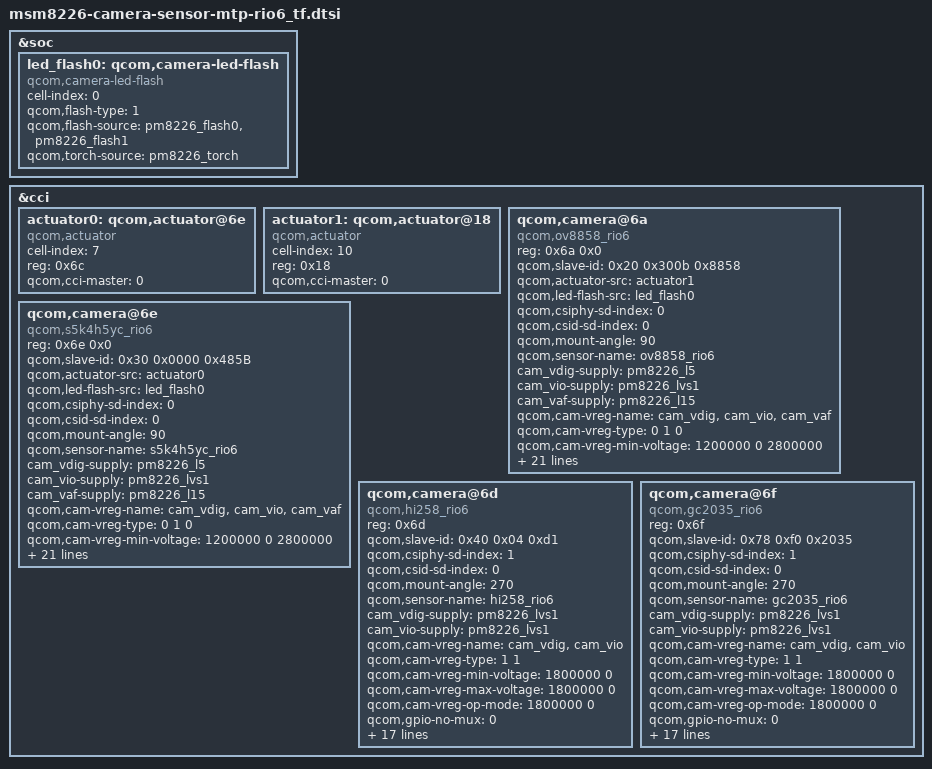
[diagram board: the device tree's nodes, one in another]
/*
 * Copyright (c) 2013, The Linux Foundation. All rights reserved.
 *
 * This program is free software; you can redistribute it and/or modify
 * it under the terms of the GNU General Public License version 2 and
 * only version 2 as published by the Free Software Foundation.
 *
 * This program is distributed in the hope that it will be useful,
 * but WITHOUT ANY WARRANTY; without even the implied warranty of
 * MERCHANTABILITY or FITNESS FOR A PARTICULAR PURPOSE.  See the
 * GNU General Public License for more details.
 *         Modify History For This Module
 * When           Who             What,Where,Why
 * --------------------------------------------------------------------------------------
 * 13/08/22      Hu Jin       Add driver for RoilTF's 1st main CAM
 * 13/12/11      Hu Jin       for i2c compatibility
 * 14/01/09      Hu Jin       Delete the old i2c
 * --------------------------------------------------------------------------------------
 */

&soc {

	led_flash0: qcom,camera-led-flash {
		cell-index = <0>;
		compatible = "qcom,camera-led-flash";
		qcom,flash-type = <1>;
		qcom,flash-source = <&pm8226_flash0 &pm8226_flash1>;
		qcom,torch-source = <&pm8226_torch>;
	};
};

&cci {

	actuator0: qcom,actuator@6e {
		cell-index = <7>;/* [PLATFORM]-Mod-BEGIN by TCTNB.HJ, 2013/11/09, 1st main CAM dev*/
		reg = <0x6c>;
		compatible = "qcom,actuator";
		qcom,cci-master = <0>;
	};
/* [PLATFORM]-Mod-BEGIN by TCTNB.HJ, 2013/12/11 */
/*
	qcom,camera@6f {
		compatible = "qcom,ov8825";
		reg = <0x6f>;
		qcom,slave-id = <0x6c 0x300a 0x8825>;
		qcom,csiphy-sd-index = <0>;
		qcom,csid-sd-index = <0>;
		qcom,actuator-src = <&actuator0>;
		qcom,led-flash-src = <&led_flash0>;
		qcom,mount-angle = <270>;
		qcom,sensor-name = "ov8825";
		cam_vdig-supply = <&pm8226_l5>;
		cam_vana-supply = <&pm8226_l19>;
		cam_vio-supply = <&pm8226_lvs1>;
		cam_vaf-supply = <&pm8226_l15>;
		qcom,cam-vreg-name = "cam_vdig", "cam_vio", "cam_vana",
							 "cam_vaf";
		qcom,cam-vreg-type = <0 1 0 0>;
		qcom,cam-vreg-min-voltage = <1200000 0 2850000 2800000>;
		qcom,cam-vreg-max-voltage = <1200000 0 2850000 2800000>;
		qcom,cam-vreg-op-mode = <200000 0 80000 100000>;
		qcom,gpio-no-mux = <0>;
		gpios = <&msmgpio 26 0>,
			<&msmgpio 37 0>,
			<&msmgpio 35 0>;
		qcom,gpio-reset = <1>;
		qcom,gpio-standby = <2>;
		qcom,gpio-req-tbl-num = <0 1 2>;
		qcom,gpio-req-tbl-flags = <1 0 0>;
		qcom,gpio-req-tbl-label = "CAMIF_MCLK",
			"CAM_RESET1",
			"CAM_STANDBY";
		qcom,csi-lane-assign = <0x4320>;
		qcom,csi-lane-mask = <0x1f>;
		qcom,sensor-position = <0>;
		qcom,sensor-mode = <1>;
		qcom,cci-master = <0>;
	};

	qcom,camera@6d {
		compatible = "qcom,ov9724";
		reg = <0x6d>;
		qcom,slave-id = <0x20 0x0 0x9724>;
		qcom,csiphy-sd-index = <1>;
		qcom,csid-sd-index = <1>;
		qcom,mount-angle = <270>;
		qcom,sensor-name = "ov9724";
		cam_vdig-supply = <&pm8226_l5>;
		cam_vana-supply = <&pm8226_l19>;
		cam_vio-supply = <&pm8226_lvs1>;
		qcom,cam-vreg-name = "cam_vdig", "cam_vio", "cam_vana";
		qcom,cam-vreg-type = <0 1 0>;
		qcom,cam-vreg-min-voltage = <1200000 0 2850000>;
		qcom,cam-vreg-max-voltage = <1200000 0 2850000>;
		qcom,cam-vreg-op-mode = <200000 0 80000>;
		qcom,gpio-no-mux = <0>;
		gpios = <&msmgpio 26 0>,
				<&msmgpio 28 0>,
				<&msmgpio 36 0>;
		qcom,gpio-reset = <1>;
		qcom,gpio-standby = <2>;
		qcom,gpio-req-tbl-num = <0 1 2>;
		qcom,gpio-req-tbl-flags = <1 0 0>;
		qcom,gpio-req-tbl-label = "CAMIF_MCLK",
				"CAM_RESET",
				"CAM_STANDBY";
		qcom,gpio-set-tbl-num = <1 1>;
		qcom,gpio-set-tbl-flags = <0 2>;
		qcom,gpio-set-tbl-delay = <1000 4000>;
		qcom,csi-lane-assign = <0x4320>;
		qcom,csi-lane-mask = <0x3>;
		qcom,sensor-position = <1>;
		qcom,sensor-mode = <1>;
		qcom,cci-master = <0>;
		status = "ok";
	};
*/
/* [PLATFORM]-Mod-END by TCTNB.HJ, 2013/12/11 */

/* [PLATFORM]-Add-BEGIN by TCTNB.WPL, 2014/01/02, 2nd main CAM OV8858 dev, refer to bug552174 */
	actuator1: qcom,actuator@18 {
		cell-index = <10>;
		reg = <0x18>;
		compatible = "qcom,actuator";
		qcom,cci-master = <0>;
	};
    qcom,camera@6a {
        compatible = "qcom,ov8858_rio6";
        reg = <0x6a 0x0>;
        qcom,slave-id = <0x20 0x300b 0x8858>;
        qcom,actuator-src = <&actuator1>;
        qcom,led-flash-src = <&led_flash0>;
        qcom,csiphy-sd-index = <0>;
        qcom,csid-sd-index = <0>;
        qcom,mount-angle = <90>;
        qcom,sensor-name = "ov8858_rio6";
        cam_vdig-supply = <&pm8226_l5>;
        cam_vio-supply = <&pm8226_lvs1>;
        cam_vaf-supply = <&pm8226_l15>;
        qcom,cam-vreg-name = "cam_vdig","cam_vio", "cam_vaf";
        qcom,cam-vreg-type = <0 1 0>;

        qcom,cam-vreg-min-voltage = <1200000 0 2800000>;
        qcom,cam-vreg-max-voltage = <1200000 0 2800000>;
        qcom,cam-vreg-op-mode = <200000 0 100000>;

        qcom,gpio-no-mux = <0>;
        gpios = <&msmgpio 26 0>,
                <&msmgpio 37 0>,
                <&msmgpio 36 0>,
                <&msmgpio 31 0>,
                <&msmgpio 23 0>;
        qcom,gpio-reset = <1>;
        qcom,gpio-standby = <2>;
           qcom,gpio-vana = <3>;
           qcom,gpio-af-pwdm = <4>;
        qcom,gpio-req-tbl-num = <0 1 2 3 4>;
        qcom,gpio-req-tbl-flags = <1 0 0 0 0>;
        qcom,gpio-req-tbl-label = "CAMIF_MCLK",
                "CAM_RESET",
                "CAM_STANDBY",
                "CAM_VANA",
                "CAM_AF_PWDM";
        qcom,gpio-set-tbl-flags = <0 2>;
        qcom,gpio-set-tbl-delay = <1000 4000>;
        qcom,csi-lane-assign = <0x4320>;
        qcom,csi-lane-mask = <0x3>;
        qcom,sensor-position = <0>;
        qcom,sensor-mode = <0>;
        qcom,cci-master = <0>;
    };
/* [PLATFORM]-Add-END by TCTNB.WPL, 2014/01/02 */

/* [PLATFORM]-Mod-BEGIN by TCTNB.HJ, 2013/12/11, 1st main CAM dev*/
    qcom,camera@6e {
        compatible = "qcom,s5k4h5yc_rio6";
        reg = <0x6e 0x0>;
        qcom,slave-id = <0x30 0x0000 0x485B>;
        qcom,actuator-src = <&actuator0>;
        qcom,led-flash-src = <&led_flash0>;
        qcom,csiphy-sd-index = <0>;
        qcom,csid-sd-index = <0>;
        qcom,mount-angle = <90>;
        qcom,sensor-name = "s5k4h5yc_rio6";
        cam_vdig-supply = <&pm8226_l5>;
        cam_vio-supply = <&pm8226_lvs1>;
        cam_vaf-supply = <&pm8226_l15>;
        qcom,cam-vreg-name = "cam_vdig","cam_vio", "cam_vaf";
        qcom,cam-vreg-type = <0 1 0>;
        qcom,cam-vreg-min-voltage = <1200000 0 2800000>;
        qcom,cam-vreg-max-voltage = <1200000 0 2800000>;
        qcom,cam-vreg-op-mode = <200000 0 100000>;
        qcom,gpio-no-mux = <0>;
        gpios = <&msmgpio 26 0>,
                <&msmgpio 37 0>,
                <&msmgpio 36 0>,
                <&msmgpio 31 0>,
                <&msmgpio 23 0>;
        qcom,gpio-reset = <1>;
        qcom,gpio-standby = <2>;
           qcom,gpio-vana = <3>;
           qcom,gpio-af-pwdm = <4>;
        qcom,gpio-req-tbl-num = <0 1 2 3 4>;
        qcom,gpio-req-tbl-flags = <1 0 0 0 0>;
        qcom,gpio-req-tbl-label = "CAMIF_MCLK",
                "CAM_RESET",
                "CAM_STANDBY",
                "CAM_VANA",
                "CAM_AF_PWDM";
        qcom,gpio-set-tbl-flags = <0 2>;
        qcom,gpio-set-tbl-delay = <1000 4000>;
        qcom,csi-lane-assign = <0x4320>;
        qcom,csi-lane-mask = <0x3>;
        qcom,sensor-position = <0>;
        qcom,sensor-mode = <0>;
        qcom,cci-master = <0>;
    };
/* [PLATFORM]-Mod-END by TCTNB.HJ, 2013/11/01 */

/* [PLATFORM]-Add-BEGIN by TCTNB.WPL, 2013/11/29, 1st sub CAM Hi258 dev, refer to bug549457*/
	qcom,camera@6d {
	compatible = "qcom,hi258_rio6";
	reg = <0x6d>;
	qcom,slave-id = <0x40 0x04 0xd1>;
	qcom,csiphy-sd-index = <1>;
	qcom,csid-sd-index = <0>;
	qcom,mount-angle = <270>;
	qcom,sensor-name = "hi258_rio6";
	cam_vdig-supply = <&pm8226_lvs1>;
	cam_vio-supply = <&pm8226_lvs1>;
	qcom,cam-vreg-name = "cam_vdig", "cam_vio";
	qcom,cam-vreg-type = <1 1>;
	qcom,cam-vreg-min-voltage = <1800000 0>;
	qcom,cam-vreg-max-voltage = <1800000 0>;
	qcom,cam-vreg-op-mode = <1800000 0>;
	qcom,gpio-no-mux = <0>;
	gpios = <&msmgpio 26 0>,
			<&msmgpio 28 0>,
			<&msmgpio 35 0>,
			<&msmgpio 31 0>;
	qcom,gpio-reset = <1>;
	qcom,gpio-standby = <2>;
       qcom,gpio-vana = <3>;
	qcom,gpio-req-tbl-num = <0 1 2 3>;
	qcom,gpio-req-tbl-flags = <1 0 0 0>;
	qcom,gpio-req-tbl-label = "CAMIF_MCLK",
			"CAM_RESET",
			"CAM_STANDBY",
			"CAM_VANA";
	qcom,gpio-set-tbl-num = <1 1>;
	qcom,gpio-set-tbl-flags = <0 2>;
	qcom,gpio-set-tbl-delay = <1000 4000>;
	qcom,csi-lane-assign = <0x4320>;
	qcom,csi-lane-mask = <0x3>;
	qcom,sensor-position = <1>;
	qcom,sensor-mode = <1>;
	qcom,cci-master = <0>;
    status = "ok";
	};
/* [PLATFORM]-Add-END by TCTNB.WPL, 2013/11/29 */

/* [PLATFORM]-Add-BEGIN by TCTNB.WPL, 2014/01/02, 2nd sub CAM GC2035 dev, refer to bug580548 */
	qcom,camera@6f {
	compatible = "qcom,gc2035_rio6";
	reg = <0x6f>;
	qcom,slave-id = <0x78 0xf0 0x2035>;
	qcom,csiphy-sd-index = <1>;
	qcom,csid-sd-index = <0>;
	qcom,mount-angle = <270>;
	qcom,sensor-name = "gc2035_rio6";
	cam_vdig-supply = <&pm8226_lvs1>;
	cam_vio-supply = <&pm8226_lvs1>;
	qcom,cam-vreg-name = "cam_vdig", "cam_vio";
	qcom,cam-vreg-type = <1 1>;
	qcom,cam-vreg-min-voltage = <1800000 0>;
	qcom,cam-vreg-max-voltage = <1800000 0>;
	qcom,cam-vreg-op-mode = <1800000 0>;
	qcom,gpio-no-mux = <0>;
	gpios = <&msmgpio 26 0>,
			<&msmgpio 28 0>,
			<&msmgpio 35 0>,
			<&msmgpio 31 0>;
	qcom,gpio-reset = <1>;
	qcom,gpio-standby = <2>;
       qcom,gpio-vana = <3>;
	qcom,gpio-req-tbl-num = <0 1 2 3>;
	qcom,gpio-req-tbl-flags = <1 0 0 0>;
	qcom,gpio-req-tbl-label = "CAMIF_MCLK",
			"CAM_RESET",
			"CAM_STANDBY",
			"CAM_VANA";
	qcom,gpio-set-tbl-num = <1 1>;
	qcom,gpio-set-tbl-flags = <0 2>;
	qcom,gpio-set-tbl-delay = <1000 4000>;
	qcom,csi-lane-assign = <0x4320>;
	qcom,csi-lane-mask = <0x3>;
	qcom,sensor-position = <1>;
	qcom,sensor-mode = <1>;
	qcom,cci-master = <0>;
    status = "ok";
	};
/* [PLATFORM]-Add-END by TCTNB.WPL, 2014/01/02 */
};
